# DVL_STM32_LIKE register map
Registers are access not given, no defined reset value unless marked. A register's access mark holds for its fields unless they carry their own. Offsets are from the block's base; lines under a group give offsets from that group; [hi:lo] are bit positions; {n}, {i} and the like mark numbered series; 'fields as' and 'values as' point back to an identical list; <NAME> marks a mode.

## Memory map
0x40004400 USART2 size 0x400
0x40013800 USART1 size 0x400

## USART1
Base 0x40013800
Same registers: USART2 0x40004400
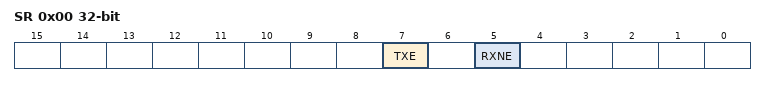
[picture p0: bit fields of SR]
0x00 SR
  [7] TXE, [5] RXNE
0x04 DR
